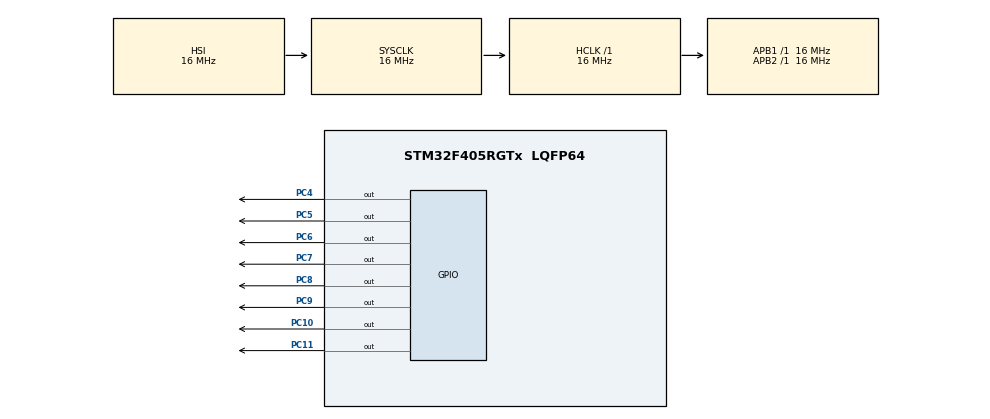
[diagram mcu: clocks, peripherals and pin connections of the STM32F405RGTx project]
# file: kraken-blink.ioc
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Mcu.Family=STM32F4
Mcu.Name=STM32F405RGTx
Mcu.Package=LQFP64
NVIC.PriorityGroup=NVIC_PRIORITYGROUP_4
PC10.Signal=GPIO_Output
PC11.Signal=GPIO_Output
PC4.Signal=GPIO_Output
PC5.Signal=GPIO_Output
PC6.Signal=GPIO_Output
PC7.Signal=GPIO_Output
PC8.Signal=GPIO_Output
PC9.Signal=GPIO_Output
ProjectManager.HeapSize=0x200
ProjectManager.StackSize=0x400
ProjectManager.TargetToolchain=Makefile
RCC.AHBFreq_Value=16000000
RCC.APB1Freq_Value=16000000
RCC.APB2Freq_Value=16000000
RCC.CortexFreq_Value=16000000
RCC.HSE_VALUE=25000000
RCC.HSI_VALUE=16000000
RCC.LSE_VALUE=32768
RCC.SYSCLKFreq_VALUE=16000000
RCC.VCOOutputFreq_Value=192000000
board=kraken-blink

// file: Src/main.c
/* vim: set ai et ts=4 sw=4: */
#include "main.h"
#include "stm32f4xx_hal.h"

/* USER CODE BEGIN PV */
/* Private variables ---------------------------------------------------------*/

/* USER CODE END PV */

void SystemClock_Config(void);
static void MX_GPIO_Init(void);

/* USER CODE BEGIN PFP */
/* Private function prototypes -----------------------------------------------*/

/* USER CODE END PFP */

/* USER CODE BEGIN 0 */
void init() {
    /* do nothing, yet */
}

void loop() {
    static const int pins[] = {
        GPIO_PIN_4, GPIO_PIN_5, GPIO_PIN_6, GPIO_PIN_7,
        GPIO_PIN_8, GPIO_PIN_9, GPIO_PIN_11, GPIO_PIN_10
    };

    for(int i = 0; i < sizeof(pins)/sizeof(pins[0]); i++) {
        HAL_GPIO_TogglePin(GPIOC, pins[i]);
        HAL_Delay(250);
    }
}

/* USER CODE END 0 */

int main(void)
{

  /* MCU Configuration----------------------------------------------------------*/

  /* Reset of all peripherals, Initializes the Flash interface and the Systick. */
  HAL_Init();

  /* Configure the system clock */
  SystemClock_Config();

  /* Initialize all configured peripherals */
  MX_GPIO_Init();

  /* Infinite loop */
  /* USER CODE BEGIN WHILE */
  init();
  while (1)
  {
    loop();
  /* USER CODE END WHILE */

  }

}

/** System Clock Configuration
*/
void SystemClock_Config(void)
{

  RCC_OscInitTypeDef RCC_OscInitStruct;
  RCC_ClkInitTypeDef RCC_ClkInitStruct;

    /**Configure the main internal regulator output voltage
    */
  __HAL_RCC_PWR_CLK_ENABLE();

  __HAL_PWR_VOLTAGESCALING_CONFIG(PWR_REGULATOR_VOLTAGE_SCALE1);

    /**Initializes the CPU, AHB and APB busses clocks
    */
  RCC_OscInitStruct.OscillatorType = RCC_OSCILLATORTYPE_HSI;
  RCC_OscInitStruct.HSIState = RCC_HSI_ON;
  RCC_OscInitStruct.HSICalibrationValue = 16;
  RCC_OscInitStruct.PLL.PLLState = RCC_PLL_NONE;
  if (HAL_RCC_OscConfig(&RCC_OscInitStruct) != HAL_OK)
  {
    _Error_Handler(__FILE__, __LINE__);
  }

    /**Initializes the CPU, AHB and APB busses clocks
    */
  RCC_ClkInitStruct.ClockType = RCC_CLOCKTYPE_HCLK|RCC_CLOCKTYPE_SYSCLK
                              |RCC_CLOCKTYPE_PCLK1|RCC_CLOCKTYPE_PCLK2;
  RCC_ClkInitStruct.SYSCLKSource = RCC_SYSCLKSOURCE_HSI;
  RCC_ClkInitStruct.AHBCLKDivider = RCC_SYSCLK_DIV1;
  RCC_ClkInitStruct.APB1CLKDivider = RCC_HCLK_DIV1;
  RCC_ClkInitStruct.APB2CLKDivider = RCC_HCLK_DIV1;

  if (HAL_RCC_ClockConfig(&RCC_ClkInitStruct, FLASH_LATENCY_0) != HAL_OK)
  {
    _Error_Handler(__FILE__, __LINE__);
  }

    /**Configure the Systick interrupt time
    */
  HAL_SYSTICK_Config(HAL_RCC_GetHCLKFreq()/1000);

    /**Configure the Systick
    */
  HAL_SYSTICK_CLKSourceConfig(SYSTICK_CLKSOURCE_HCLK);

  /* SysTick_IRQn interrupt configuration */
  HAL_NVIC_SetPriority(SysTick_IRQn, 0, 0);
}

/** Configure pins as
        * Analog
        * Input
        * Output
        * EVENT_OUT
        * EXTI
*/
static void MX_GPIO_Init(void)
{

  GPIO_InitTypeDef GPIO_InitStruct;

  /* GPIO Ports Clock Enable */
  __HAL_RCC_GPIOC_CLK_ENABLE();

  /*Configure GPIO pin Output Level */
  HAL_GPIO_WritePin(GPIOC, GPIO_PIN_4|GPIO_PIN_5|GPIO_PIN_6|GPIO_PIN_7
                          |GPIO_PIN_8|GPIO_PIN_9|GPIO_PIN_10|GPIO_PIN_11, GPIO_PIN_RESET);

  /*Configure GPIO pins : PC4 PC5 PC6 PC7
                           PC8 PC9 PC10 PC11 */
  GPIO_InitStruct.Pin = GPIO_PIN_4|GPIO_PIN_5|GPIO_PIN_6|GPIO_PIN_7
                          |GPIO_PIN_8|GPIO_PIN_9|GPIO_PIN_10|GPIO_PIN_11;
  GPIO_InitStruct.Mode = GPIO_MODE_OUTPUT_PP;
  GPIO_InitStruct.Pull = GPIO_NOPULL;
  GPIO_InitStruct.Speed = GPIO_SPEED_FREQ_LOW;
  HAL_GPIO_Init(GPIOC, &GPIO_InitStruct);

}

void _Error_Handler(char * file, int line)
{
  while(1)
  {
  }
}

/************************ (C) COPYRIGHT STMicroelectronics *****END OF FILE****/
